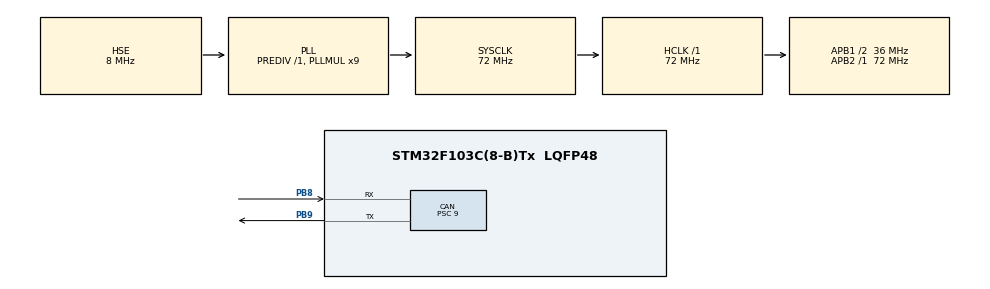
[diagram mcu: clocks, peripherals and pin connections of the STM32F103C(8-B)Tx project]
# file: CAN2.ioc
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CAN.BS1=CAN_BS1_13TQ
CAN.BS2=CAN_BS2_2TQ
CAN.CalculateTimeBit=4000
CAN.CalculateTimeQuantum=250.0
CAN.Mode=CAN_MODE_SILENT_LOOPBACK
CAN.NART=ENABLE
CAN.Prescaler=9
CAN.TXFP=ENABLE
Mcu.Family=STM32F1
Mcu.Name=STM32F103C(8-B)Tx
Mcu.Package=LQFP48
NVIC.PriorityGroup=NVIC_PRIORITYGROUP_4
NVIC.USB_LP_CAN1_RX0_IRQn=true\:0\:0\:false\:true\:true\:1\:true\:true
PA13.Mode=Serial_Wire
PA13.Signal=SYS_JTMS-SWDIO
PA14.Mode=Serial_Wire
PA14.Signal=SYS_JTCK-SWCLK
PB8.Mode=Master
PB8.Signal=CAN_RX
PB9.Mode=Master
PB9.Signal=CAN_TX
PD0-OSC_IN.Mode=HSE-External-Oscillator
PD0-OSC_IN.Signal=RCC_OSC_IN
PD1-OSC_OUT.Mode=HSE-External-Oscillator
PD1-OSC_OUT.Signal=RCC_OSC_OUT
ProjectManager.HeapSize=0x200
ProjectManager.StackSize=0x400
ProjectManager.TargetToolchain=MDK-ARM V5.27
RCC.AHBFreq_Value=72000000
RCC.APB1CLKDivider=RCC_HCLK_DIV2
RCC.APB1Freq_Value=36000000
RCC.APB1TimFreq_Value=72000000
RCC.APB2Freq_Value=72000000
RCC.APB2TimFreq_Value=72000000
RCC.HCLKFreq_Value=72000000
RCC.PLLMUL=RCC_PLL_MUL9
RCC.PLLSourceVirtual=RCC_PLLSOURCE_HSE
RCC.SYSCLKFreq_VALUE=72000000
RCC.SYSCLKSource=RCC_SYSCLKSOURCE_PLLCLK
RCC.USBFreq_Value=72000000
board=custom

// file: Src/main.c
/* USER CODE BEGIN Header */
/**
  ******************************************************************************
  * @file           : main.c
  * @brief          : Main program body
  ******************************************************************************
  * @attention
  *
  * <h2><center>&copy; Copyright (c) 2020 STMicroelectronics.
  * All rights reserved.</center></h2>
  *
  * This software component is licensed by ST under BSD 3-Clause license,
  * the "License"; You may not use this file except in compliance with the
  * License. You may obtain a copy of the License at:
  *                        opensource.org/licenses/BSD-3-Clause
  *
  ******************************************************************************
  */
/* USER CODE END Header */

#include "main.h"

CAN_HandleTypeDef hcan;

/* USER CODE BEGIN PV */
uint32_t TxMailbox;
CAN_RxHeaderTypeDef rx;
uint8_t RXdata[8];
uint8_t res;
/* USER CODE END PV */

void SystemClock_Config(void);
static void MX_GPIO_Init(void);
static void MX_CAN_Init(void);
static void MX_NVIC_Init(void);

/* USER CODE BEGIN 0 */
 void HAL_CAN_RxFifo0MsgPendingCallback(CAN_HandleTypeDef * hcan)
  {
    if (HAL_CAN_GetRxMessage(hcan, CAN_RX_FIFO0, &rx, RXdata) != HAL_OK)
    {
      Error_Handler();
    }
    else
    {

    }
  }
/* USER CODE END 0 */

int main(void)
{

  /* MCU Configuration--------------------------------------------------------*/

  /* Reset of all peripherals, Initializes the Flash interface and the Systick. */
  HAL_Init();

  /* Configure the system clock */
  SystemClock_Config();

  /* Initialize all configured peripherals */
  MX_GPIO_Init();
  MX_CAN_Init();

  /* Initialize interrupts */
  MX_NVIC_Init();
  /* USER CODE BEGIN 2 */

	CAN_TxHeaderTypeDef tx;
	tx.DLC = 8;
	tx.ExtId = 0x122;
	tx.StdId = 0x02;
	tx.RTR = CAN_RTR_DATA;
	tx.IDE = CAN_ID_STD;
	tx.TransmitGlobalTime = DISABLE;

	res = HAL_CAN_AddTxMessage(&hcan,&tx,(uint8_t*)"ab",&TxMailbox);
	HAL_Delay(1000);
	res = HAL_CAN_AddTxMessage(&hcan,&tx,(uint8_t*)"bc",&TxMailbox);
  /* USER CODE END 2 */

  /* Infinite loop */
  /* USER CODE BEGIN WHILE */

	//HAL_CAN_GetRxFifoFillLevel(&hcan,);
  while (1)
  {
    /* USER CODE END WHILE */

  }
}

void SystemClock_Config(void)
{
  RCC_OscInitTypeDef RCC_OscInitStruct = {0};
  RCC_ClkInitTypeDef RCC_ClkInitStruct = {0};

  /** Initializes the CPU, AHB and APB busses clocks
  */
  RCC_OscInitStruct.OscillatorType = RCC_OSCILLATORTYPE_HSE;
  RCC_OscInitStruct.HSEState = RCC_HSE_ON;
  RCC_OscInitStruct.HSEPredivValue = RCC_HSE_PREDIV_DIV1;
  RCC_OscInitStruct.HSIState = RCC_HSI_ON;
  RCC_OscInitStruct.PLL.PLLState = RCC_PLL_ON;
  RCC_OscInitStruct.PLL.PLLSource = RCC_PLLSOURCE_HSE;
  RCC_OscInitStruct.PLL.PLLMUL = RCC_PLL_MUL9;
  if (HAL_RCC_OscConfig(&RCC_OscInitStruct) != HAL_OK)
  {
    Error_Handler();
  }
  /** Initializes the CPU, AHB and APB busses clocks
  */
  RCC_ClkInitStruct.ClockType = RCC_CLOCKTYPE_HCLK|RCC_CLOCKTYPE_SYSCLK
                              |RCC_CLOCKTYPE_PCLK1|RCC_CLOCKTYPE_PCLK2;
  RCC_ClkInitStruct.SYSCLKSource = RCC_SYSCLKSOURCE_PLLCLK;
  RCC_ClkInitStruct.AHBCLKDivider = RCC_SYSCLK_DIV1;
  RCC_ClkInitStruct.APB1CLKDivider = RCC_HCLK_DIV2;
  RCC_ClkInitStruct.APB2CLKDivider = RCC_HCLK_DIV1;

  if (HAL_RCC_ClockConfig(&RCC_ClkInitStruct, FLASH_LATENCY_2) != HAL_OK)
  {
    Error_Handler();
  }
}

/**
  * @brief NVIC Configuration.
  * @retval None
  */
static void MX_NVIC_Init(void)
{
  /* USB_LP_CAN1_RX0_IRQn interrupt configuration */
  HAL_NVIC_SetPriority(USB_LP_CAN1_RX0_IRQn, 0, 0);
  HAL_NVIC_EnableIRQ(USB_LP_CAN1_RX0_IRQn);
}

static void MX_CAN_Init(void)
{

  /* USER CODE BEGIN CAN_Init 0 */
	__HAL_RCC_CAN1_CLK_ENABLE();

	GPIO_InitTypeDef GPIO_InitStruct;

	GPIO_InitStruct.Pin = GPIO_PIN_11;
  GPIO_InitStruct.Mode = GPIO_MODE_INPUT;
  GPIO_InitStruct.Pull = GPIO_PULLUP;
  GPIO_InitStruct.Speed = GPIO_SPEED_FREQ_HIGH;
  HAL_GPIO_Init(GPIOA, &GPIO_InitStruct);

	GPIO_InitStruct.Pin = GPIO_PIN_12;
  GPIO_InitStruct.Mode = GPIO_MODE_AF_PP;
  GPIO_InitStruct.Pull = GPIO_NOPULL;
  GPIO_InitStruct.Speed = GPIO_SPEED_FREQ_HIGH;
  HAL_GPIO_Init(GPIOA, &GPIO_InitStruct);
  /* USER CODE END CAN_Init 0 */

  hcan.Instance = CAN1;
  hcan.Init.Prescaler = 9;
  hcan.Init.Mode = CAN_MODE_SILENT_LOOPBACK;
  hcan.Init.SyncJumpWidth = CAN_SJW_1TQ;
  hcan.Init.TimeSeg1 = CAN_BS1_13TQ;
  hcan.Init.TimeSeg2 = CAN_BS2_2TQ;
  hcan.Init.TimeTriggeredMode = DISABLE;
  hcan.Init.AutoBusOff = DISABLE;
  hcan.Init.AutoWakeUp = DISABLE;
  hcan.Init.AutoRetransmission = ENABLE;
  hcan.Init.ReceiveFifoLocked = DISABLE;
  hcan.Init.TransmitFifoPriority = ENABLE;
  if (HAL_CAN_Init(&hcan) != HAL_OK)
  {
    Error_Handler();
  }
  /* USER CODE BEGIN CAN_Init 2 */
	CAN_FilterTypeDef filter;
	filter.FilterBank = 0;
	filter.FilterActivation = ENABLE;
	filter.FilterFIFOAssignment = CAN_RX_FIFO0;
	filter.FilterIdHigh = 0x0000;
	filter.FilterIdLow = 0x0000;
	filter.FilterMaskIdHigh = 0x0000;
	filter.FilterMaskIdLow = 0x0000;
	filter.FilterMode = CAN_FILTERMODE_IDMASK;
	filter.FilterScale = CAN_FILTERSCALE_32BIT;
	filter.SlaveStartFilterBank = 0;

	HAL_CAN_ConfigFilter(&hcan,&filter);

	HAL_CAN_Start(&hcan);

	HAL_CAN_ActivateNotification(&hcan,CAN_IT_RX_FIFO0_MSG_PENDING);
  /* USER CODE END CAN_Init 2 */

}

static void MX_GPIO_Init(void)
{

  /* GPIO Ports Clock Enable */
  __HAL_RCC_GPIOD_CLK_ENABLE();
  __HAL_RCC_GPIOA_CLK_ENABLE();
  __HAL_RCC_GPIOB_CLK_ENABLE();

}

void Error_Handler(void)
{
}

/************************ (C) COPYRIGHT STMicroelectronics *****END OF FILE****/
